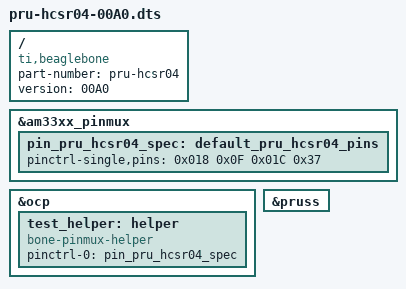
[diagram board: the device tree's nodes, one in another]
/*
 * Copyright (C) 2013 Nathaniel R. Lewis - http://nathanielrlewis.com/
 *
 * This program is free software; you can redistribute it and/or modify
 * it under the terms of the GNU General Public License version 2 as
 * published by the Free Software Foundation.
 * 
 * Setup pinmux for the 
 */
/dts-v1/;
/plugin/;

/ {
    compatible = "ti,beaglebone", "ti,beaglebone-black";

    /* identification */
    part-number = "pru-hcsr04";
    version     = "00A0";

    fragment@0 {
        target = <&am33xx_pinmux>;
        __overlay__ {
        	pin_pru_hcsr04_spec: default_pru_hcsr04_pins {
        		pinctrl-single,pins = <
                        0x018 0x0F  /* GPIO1_6, MODE7 */
                        0x01C 0x37  /* GPIO1_7, MODE7 */ 
        		>;
        	};
        };
    };
    
    fragment@1 {
		target = <&ocp>;
		__overlay__ {
			test_helper: helper {
				compatible = "bone-pinmux-helper";
				pinctrl-names = "default";
				pinctrl-0 = <&pin_pru_hcsr04_spec>;
				status = "okay";
			};
		};
	};
    
    fragment@2 {
        target = <&pruss>;
        __overlay__ {
            status = "okay";
        };
    };
};
